# MK21FA12 register map
Vendor: Freescale Semiconductor, Inc.; Series: Kinetis_K; File version: 1.6
CPU: CM4 r0p1, little endian, no MPU, FPU, VTOR, 4 interrupt priority bits
Registers are 32-bit, read-write, reset 0x0 unless marked. A register's access mark holds for its fields unless they carry their own. Offsets are from the block's base; [hi:lo] are bit positions; {n}, {i} and the like mark numbered series; 'fields as' and 'values as' point back to an identical list.

## AXBS — Crossbar switch
Base 0x40004000; register names take the prefix AXBS_
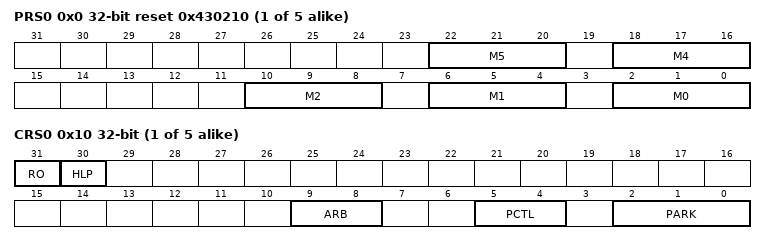
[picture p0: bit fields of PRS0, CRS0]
{0x0+0x100*i} PRS{i} (i=0..4) reset 0x430210 — Priority Registers Slave
  [all] fields
    0=This master has level 1, or highest, priority when accessing the slave port; {v}=This master has level {v+1} priority when accessing the slave port (v=1..6); 7=This master has level 8, or lowest, priority when accessing the slave port
  [22:20] M5 — Master 5 Priority. Sets the arbitration priority for this port on the associated slave port.
  [18:16] M4 — Master 4 Priority. Sets the arbitration priority for this port on the associated slave port.
  [10:8] M2 — Master 2 Priority. Sets the arbitration priority for this port on the associated slave port.
  [6:4] M1 — Master 1 Priority. Sets the arbitration priority for this port on the associated slave port.
  [2:0] M0 — Master 0 Priority. Sets the arbitration priority for this port on the associated slave port.
{0x10+0x100*i} CRS{i} (i=0..4) — Control Register
  [31] RO — Read Only
    0=The slave port's registers are writeable; 1=The slave port's registers are read-only and cannot be written. Attempted writes have no effect on the registers and result in a bus error response.
  [30] HLP — Halt Low Priority
    0=The low power mode request has the highest priority for arbitration on this slave port; 1=The low power mode request has the lowest initial priority for arbitration on this slave port
  [9:8] ARB — Arbitration Mode
    0=Fixed priority; 1=Round-robin, or rotating, priority
  [5:4] PCTL — Parking Control
    0=When no master makes a request, the arbiter parks the slave port on the master port defined by the PARK field; 1=When no master makes a request, the arbiter parks the slave port on the last master to be in control of the slave port; 2=When no master makes a request, the slave port is not parked on a master and the arbiter drives all outputs to a constant safe state
  [2:0] PARK
    {v}=Park on master port M{v} (v=0..7)
{0x800+0x100*i} MGPCR{i} (i=0..2) — Master General Purpose Control Register
  [2:0] AULB — Arbitrates On Undefined Length Bursts
    0=No arbitration is allowed during an undefined length burst; 1=Arbitration is allowed at any time during an undefined length burst; 2=Arbitration is allowed after four beats of an undefined length burst; 3=Arbitration is allowed after eight beats of an undefined length burst; 4=Arbitration is allowed after 16 beats of an undefined length burst
0xC00 MGPCR4 — Master General Purpose Control Register
  fields as MGPCR0
0xD00 MGPCR5 — Master General Purpose Control Register
  fields as MGPCR0

## DMAMUX — DMA channel multiplexor
Base 0x40021000; register names take the prefix DMAMUX_
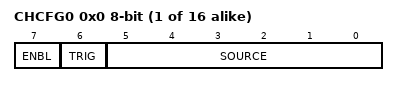
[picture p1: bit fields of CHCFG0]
{0x0+i} CHCFG{i} (i=0..15) 8-bit — Channel Configuration register
  [7] ENBL — DMA Channel Enable
    0=DMA channel is disabled. This mode is primarily used during configuration of the DMAMux. The DMA has separate channel enables/disables, which should be used to disable or reconfigure a DMA channel.; 1=DMA channel is enabled
  [6] TRIG — DMA Channel Trigger Enable
    0=Triggering is disabled. If triggering is disabled and ENBL is set, the DMA Channel will simply route the specified source to the DMA channel. (Normal mode); 1=Triggering is enabled. If triggering is enabled and ENBL is set, the DMAMUX is in Periodic Trigger mode.
  [5:0] SOURCE — DMA Channel Source (Slot)

## RNG — Random Number Generator Accelerator
Base 0x40029000; register names take the prefix RNG_
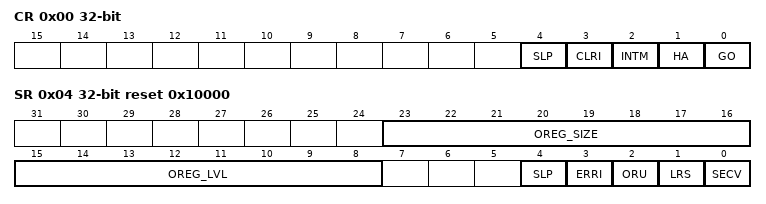
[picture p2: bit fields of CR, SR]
0x00 CR — RNGA Control Register
  [4] SLP — Sleep
    0=Normal mode; 1=Sleep (low-power) mode
  [3] CLRI wo — Clear Interrupt
    0=Do not clear the interrupt; 1=Clear the interrupt. When you write 1 to this field, RNGA then resets the error-interrupt indicator (SR[ERRI]). This bit always reads as 0.
  [2] INTM — Interrupt Mask
    0=Not masked; 1=Masked
  [1] HA — High Assurance
    0=Disabled; 1=Enabled
  [0] GO
    0=Disabled; 1=Enabled
0x04 SR ro reset 0x10000 — RNGA Status Register
  [23:16] OREG_SIZE — Output Register Size
    1=One word (this value is fixed)
  [15:8] OREG_LVL — Output Register Level
    0=No words (empty); 1=One word (valid)
  [4] SLP — Sleep
    0=Normal mode; 1=Sleep (low-power) mode
  [3] ERRI — Error Interrupt
    0=No underflow; 1=Underflow
  [2] ORU — Output Register Underflow
    0=No underflow; 1=Underflow
  [1] LRS — Last Read Status
    0=No underflow; 1=Underflow
  [0] SECV — Security Violation
    0=No security violation; 1=Security violation
0x08 ER wo — RNGA Entropy Register
  [31:0] EXT_ENT — External Entropy
0x0C OR ro — RNGA Output Register
  [31:0] RANDOUT — Random Output
    0=Invalid data (if you read this field when it is 0 and SR[OREG_LVL] is 0, RNGA then writes 1 to SR[ERRI], SR[ORU], and SR[LRS]; when the error interrupt is not masked (CR[INTM]=0), RNGA also asserts an error interrupt request to the interrupt controller)

## Notices in the file
Redistribution and use in source and binary forms, with or without modification,
are permitted provided that the following conditions are met:
o Redistributions of source code must retain the above copyright notice, this list
of conditions and the following disclaimer.
o Redistributions in binary form must reproduce the above copyright notice, this
list of conditions and the following disclaimer in the documentation and/or
other materials provided with the distribution.
o Neither the name of Freescale Semiconductor, Inc. nor the names of its
contributors may be used to endorse or promote products derived from this
software without specific prior written permission.
THIS SOFTWARE IS PROVIDED BY THE COPYRIGHT HOLDERS AND CONTRIBUTORS "AS IS" AND
ANY EXPRESS OR IMPLIED WARRANTIES, INCLUDING, BUT NOT LIMITED TO, THE IMPLIED
WARRANTIES OF MERCHANTABILITY AND FITNESS FOR A PARTICULAR PURPOSE ARE
DISCLAIMED. IN NO EVENT SHALL THE COPYRIGHT HOLDER OR CONTRIBUTORS BE LIABLE FOR
ANY DIRECT, INDIRECT, INCIDENTAL, SPECIAL, EXEMPLARY, OR CONSEQUENTIAL DAMAGES
(INCLUDING, BUT NOT LIMITED TO, PROCUREMENT OF SUBSTITUTE GOODS OR SERVICES;
LOSS OF USE, DATA, OR PROFITS; OR BUSINESS INTERRUPTION) HOWEVER CAUSED AND ON
ANY THEORY OF LIABILITY, WHETHER IN CONTRACT, STRICT LIABILITY, OR TORT
(INCLUDING NEGLIGENCE OR OTHERWISE) ARISING IN ANY WAY OUT OF THE USE OF THIS
SOFTWARE, EVEN IF ADVISED OF THE POSSIBILITY OF SUCH DAMAGE.
